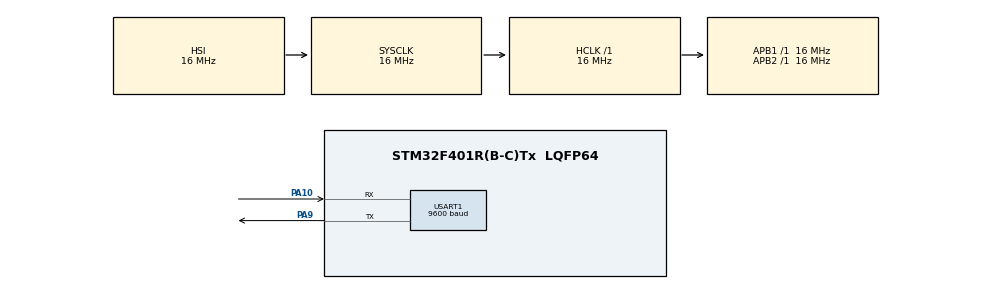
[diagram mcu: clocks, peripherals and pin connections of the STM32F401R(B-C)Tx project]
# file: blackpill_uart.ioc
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Mcu.Family=STM32F4
Mcu.Name=STM32F401R(B-C)Tx
Mcu.Package=LQFP64
NVIC.PriorityGroup=NVIC_PRIORITYGROUP_4
NVIC.USART1_IRQn=true\:0\:0\:false\:false\:true\:true\:true\:true
PA10.Mode=Asynchronous
PA10.Signal=USART1_RX
PA9.Mode=Asynchronous
PA9.Signal=USART1_TX
ProjectManager.HeapSize=0x200
ProjectManager.StackSize=0x400
ProjectManager.TargetToolchain=STM32CubeIDE
RCC.AHBFreq_Value=16000000
RCC.APB1Freq_Value=16000000
RCC.APB2Freq_Value=16000000
RCC.CortexFreq_Value=16000000
RCC.HSE_VALUE=25000000
RCC.HSI_VALUE=16000000
RCC.LSE_VALUE=32768
RCC.SYSCLKFreq_VALUE=16000000
RCC.VCOOutputFreq_Value=192000000
USART1.BaudRate=9600
USART1.VirtualMode=VM_ASYNC
board=custom

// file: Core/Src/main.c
/* USER CODE BEGIN Header */
/**
  ******************************************************************************
  * @file           : main.c
  * @brief          : Main program body
  ******************************************************************************
  * @attention
  *
  * Copyright (c) 2025 STMicroelectronics.
  * All rights reserved.
  *
  * This software is licensed under terms that can be found in the LICENSE file
  * in the root directory of this software component.
  * If no LICENSE file comes with this software, it is provided AS-IS.
  *
  ******************************************************************************
  */
/* USER CODE END Header */
#include "main.h"

/* USER CODE BEGIN Includes */

#include <string.h> //For using strlen function

/* USER CODE END Includes */

UART_HandleTypeDef huart1;

void SystemClock_Config(void);
static void MX_GPIO_Init(void);
static void MX_USART1_UART_Init(void);

/* USER CODE BEGIN 0 */

uint8_t RxData[100]; //Buffer to store the complete received data
uint8_t dataToSend[100] = "Hello from stm32f401rct6!\n\rSend any message and I will send it back :D\n\r"; //Buffer which stores welcome message as well as the data to be sent later
uint8_t RxBuffer[1]; //Buffer to store a single character to be written into the RxData buffer one by one
uint8_t position = 0; //Index to store characters in order into the RxData buffer
uint8_t isSent = 1; //Variable to check whether previous transmission is complete

void HAL_UART_RxCpltCallback(UART_HandleTypeDef *huart) //Function prototype copied from stm32f4xx_hal_uart.h file, gets called when a character has been received
{
	//Go into this if statement only if the string has been completed (whether a linefeed or carriage return is sent at the end of a string) or if the buffer is full
	if(position>=100 || RxBuffer[0] == '\n' || RxBuffer[0] == '\r')
	{
		//This for loop will fill up the empty spaces of the RxData buffer with null characters
		for(; position<100; position++)
		{
			RxData[position] = '\0';
		}
		//Reset the index back to 0 for next string
		position = 0;

		//Copy the contents of RxData buffer to dataToSend buffer for transmitting it back
		for(uint8_t i = 0; i<100; i++)
		{
			dataToSend[i] = RxData[i];
		}

		//Transmit the contents of dataToSend over UART by checking if previous transmission is complete
		if(isSent)
		{
			//Set isSent to 0 to denote that current transmission is about to start and new transmission should not happen right now
			isSent = 0;
			//strlen is used to exclude null characters from being sent
			HAL_UART_Transmit_IT(&huart1, dataToSend, strlen((char*)dataToSend));
		}
	}

	//This statement executes until the end of the string or RxData buffer becomes full, fills up RxData buffer with the received string one character at a time
	else
	{
		RxData[position] = RxBuffer[0];
		position++;
	}
	HAL_UART_Receive_IT(&huart1, RxBuffer, 1); //Be ready to receive the next character
}

void HAL_UART_TxCpltCallback(UART_HandleTypeDef *huart)
{
	//Set isSent to 1 to denote that previous transmission has completed and new transmission can be done
	isSent = 1;
}

/* USER CODE END 0 */

int main(void)
{

  /* MCU Configuration--------------------------------------------------------*/

  /* Reset of all peripherals, Initializes the Flash interface and the Systick. */
  HAL_Init();

  /* Configure the system clock */
  SystemClock_Config();

  /* Initialize all configured peripherals */
  MX_GPIO_Init();
  MX_USART1_UART_Init();
  /* USER CODE BEGIN 2 */

  //Transmit default welcome message at the start
  HAL_UART_Transmit_IT(&huart1, dataToSend, strlen((char*)dataToSend));

  //Start receiving for the first time
  HAL_UART_Receive_IT(&huart1, RxBuffer, 1);

  /* USER CODE END 2 */

  /* Infinite loop */
  while (1)
  {

  }
}

void SystemClock_Config(void)
{
  RCC_OscInitTypeDef RCC_OscInitStruct = {0};
  RCC_ClkInitTypeDef RCC_ClkInitStruct = {0};

  /** Configure the main internal regulator output voltage
  */
  __HAL_RCC_PWR_CLK_ENABLE();
  __HAL_PWR_VOLTAGESCALING_CONFIG(PWR_REGULATOR_VOLTAGE_SCALE2);

  /** Initializes the RCC Oscillators according to the specified parameters
  * in the RCC_OscInitTypeDef structure.
  */
  RCC_OscInitStruct.OscillatorType = RCC_OSCILLATORTYPE_HSI;
  RCC_OscInitStruct.HSIState = RCC_HSI_ON;
  RCC_OscInitStruct.HSICalibrationValue = RCC_HSICALIBRATION_DEFAULT;
  RCC_OscInitStruct.PLL.PLLState = RCC_PLL_NONE;
  if (HAL_RCC_OscConfig(&RCC_OscInitStruct) != HAL_OK)
  {
    Error_Handler();
  }

  /** Initializes the CPU, AHB and APB buses clocks
  */
  RCC_ClkInitStruct.ClockType = RCC_CLOCKTYPE_HCLK|RCC_CLOCKTYPE_SYSCLK
                              |RCC_CLOCKTYPE_PCLK1|RCC_CLOCKTYPE_PCLK2;
  RCC_ClkInitStruct.SYSCLKSource = RCC_SYSCLKSOURCE_HSI;
  RCC_ClkInitStruct.AHBCLKDivider = RCC_SYSCLK_DIV1;
  RCC_ClkInitStruct.APB1CLKDivider = RCC_HCLK_DIV1;
  RCC_ClkInitStruct.APB2CLKDivider = RCC_HCLK_DIV1;

  if (HAL_RCC_ClockConfig(&RCC_ClkInitStruct, FLASH_LATENCY_0) != HAL_OK)
  {
    Error_Handler();
  }
}

static void MX_USART1_UART_Init(void)
{

  huart1.Instance = USART1;
  huart1.Init.BaudRate = 9600;
  huart1.Init.WordLength = UART_WORDLENGTH_8B;
  huart1.Init.StopBits = UART_STOPBITS_1;
  huart1.Init.Parity = UART_PARITY_NONE;
  huart1.Init.Mode = UART_MODE_TX_RX;
  huart1.Init.HwFlowCtl = UART_HWCONTROL_NONE;
  huart1.Init.OverSampling = UART_OVERSAMPLING_16;
  if (HAL_UART_Init(&huart1) != HAL_OK)
  {
    Error_Handler();
  }

}

static void MX_GPIO_Init(void)
{

  /* GPIO Ports Clock Enable */
  __HAL_RCC_GPIOA_CLK_ENABLE();

}

void Error_Handler(void)
{
  __disable_irq();
  while (1)
  {
  }
}
